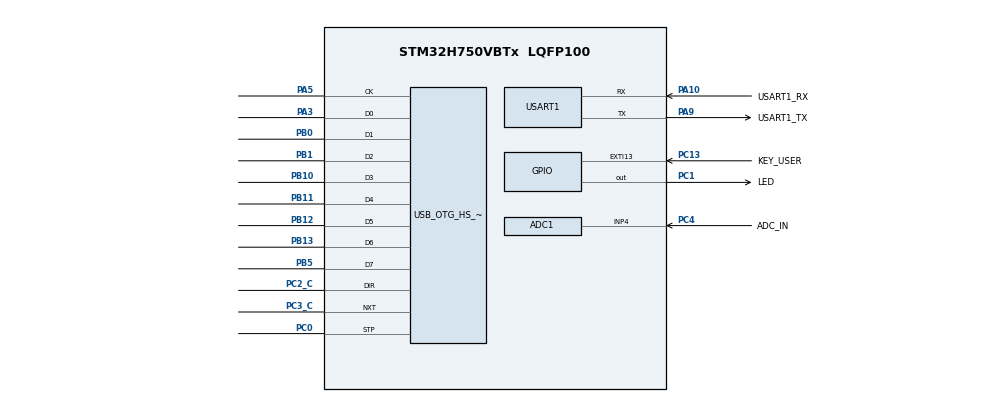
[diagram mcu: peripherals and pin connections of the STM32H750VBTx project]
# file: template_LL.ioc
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ADC1.Channel-4\#ChannelRegularConversion=ADC_CHANNEL_4
ADC1.ContinuousConvMode=DISABLE
ADC1.ConversionDataManagement=ADC_CONVERSIONDATA_DMA_ONESHOT
ADC1.DiscontinuousConvMode=DISABLE
ADC1.EnableRegularConversion=ENABLE
ADC1.ExternalTrigConv=ADC_EXTERNALTRIG_T1_TRGO
ADC1.NbrOfConversion=1
ADC1.NbrOfConversionFlag=1
ADC1.OffsetNumber-4\#ChannelRegularConversion=ADC_OFFSET_NONE
ADC1.OffsetSignedSaturation-4\#ChannelRegularConversion=DISABLE
ADC1.OversamplingMode=DISABLE
ADC1.Rank-4\#ChannelRegularConversion=1
ADC1.SamplingTime-4\#ChannelRegularConversion=ADC_SAMPLETIME_1CYCLE_5
ADC1.master=1
CORTEX_M7.CPU_DCache=Disabled
CORTEX_M7.CPU_ICache=Enabled
Dma.ADC1.0.Direction=DMA_PERIPH_TO_MEMORY
Dma.ADC1.0.EventEnable=DISABLE
Dma.ADC1.0.FIFOMode=DMA_FIFOMODE_DISABLE
Dma.ADC1.0.Instance=DMA1_Stream0
Dma.ADC1.0.MemDataAlignment=DMA_MDATAALIGN_HALFWORD
Dma.ADC1.0.MemInc=DMA_MINC_ENABLE
Dma.ADC1.0.Mode=DMA_NORMAL
Dma.ADC1.0.PeriphDataAlignment=DMA_PDATAALIGN_HALFWORD
Dma.ADC1.0.PeriphInc=DMA_PINC_DISABLE
Dma.ADC1.0.Polarity=HAL_DMAMUX_REQ_GEN_RISING
Dma.ADC1.0.Priority=DMA_PRIORITY_VERY_HIGH
Dma.ADC1.0.RequestNumber=1
Dma.ADC1.0.SignalID=NONE
Dma.ADC1.0.SyncEnable=DISABLE
Dma.ADC1.0.SyncPolarity=HAL_DMAMUX_SYNC_NO_EVENT
Dma.ADC1.0.SyncRequestNumber=1
Dma.ADC1.0.SyncSignalID=NONE
Dma.Request0=ADC1
Mcu.Family=STM32H7
Mcu.Name=STM32H750VBTx
Mcu.Package=LQFP100
NVIC.DMA1_Stream0_IRQn=true\:0\:1\:true\:false\:true\:false\:true\:true
NVIC.EXTI15_10_IRQn=true\:1\:3\:true\:false\:true\:true\:true\:true
NVIC.OTG_HS_IRQn=true\:0\:2\:false\:false\:true\:false\:true\:true
NVIC.PriorityGroup=NVIC_PRIORITYGROUP_2
NVIC.TIM2_IRQn=true\:2\:2\:true\:false\:true\:true\:true\:true
NVIC.USART1_IRQn=true\:3\:2\:true\:false\:true\:true\:true\:true
PA10.GPIO_Label=USART1_RX
PA10.Mode=Asynchronous
PA10.Signal=USART1_RX
PA13\ (JTMS/SWDIO).Mode=Serial_Wire
PA13\ (JTMS/SWDIO).Signal=DEBUG_JTMS-SWDIO
PA14\ (JTCK/SWCLK).Mode=Serial_Wire
PA14\ (JTCK/SWCLK).Signal=DEBUG_JTCK-SWCLK
PA3.Mode=Device_HS
PA3.Signal=USB_OTG_HS_ULPI_D0
PA5.Mode=Device_HS
PA5.Signal=USB_OTG_HS_ULPI_CK
PA9.GPIO_Label=USART1_TX
PA9.Mode=Asynchronous
PA9.Signal=USART1_TX
PB0.Mode=Device_HS
PB0.Signal=USB_OTG_HS_ULPI_D1
PB1.Mode=Device_HS
PB1.Signal=USB_OTG_HS_ULPI_D2
PB10.Mode=Device_HS
PB10.Signal=USB_OTG_HS_ULPI_D3
PB11.Mode=Device_HS
PB11.Signal=USB_OTG_HS_ULPI_D4
PB12.Mode=Device_HS
PB12.Signal=USB_OTG_HS_ULPI_D5
PB13.Mode=Device_HS
PB13.Signal=USB_OTG_HS_ULPI_D6
PB5.Mode=Device_HS
PB5.Signal=USB_OTG_HS_ULPI_D7
PC0.Mode=Device_HS
PC0.Signal=USB_OTG_HS_ULPI_STP
PC1.GPIO_Label=LED
PC1.Signal=GPIO_Output
PC13.GPIO_Label=KEY_USER
PC13.GPIO_ModeDefaultEXTI=GPIO_MODE_IT_FALLING
PC13.GPIO_PuPd=GPIO_PULLUP
PC13.Signal=GPXTI13
PC2_C.Mode=Device_HS
PC2_C.Signal=USB_OTG_HS_ULPI_DIR
PC3_C.Mode=Device_HS
PC3_C.Signal=USB_OTG_HS_ULPI_NXT
PC4.GPIO_Label=ADC_IN
PC4.Signal=ADCx_INP4
PH0-OSC_IN\ (PH0).Mode=HSE-External-Oscillator
PH0-OSC_IN\ (PH0).Signal=RCC_OSC_IN
PH1-OSC_OUT\ (PH1).Mode=HSE-External-Oscillator
PH1-OSC_OUT\ (PH1).Signal=RCC_OSC_OUT
ProjectManager.HeapSize=0x400
ProjectManager.StackSize=0x400
ProjectManager.TargetToolchain=MDK-ARM V5.32
RCC.ADCFreq_Value=8000000
RCC.APB1Freq_Value=100000000
RCC.APB2Freq_Value=100000000
RCC.APB3Freq_Value=100000000
RCC.APB4Freq_Value=100000000
RCC.CortexFreq_Value=50000000
RCC.Cortex_Div=SYSTICK_CLKSOURCE_HCLK_DIV8
RCC.D1PPRE=RCC_APB3_DIV2
RCC.D2PPRE1=RCC_APB1_DIV2
RCC.D2PPRE2=RCC_APB2_DIV2
RCC.D3PPRE=RCC_APB4_DIV2
RCC.DIVM1=5
RCC.DIVM2=25
RCC.DIVM3=5
RCC.DIVN1=160
RCC.DIVN2=320
RCC.DIVN3=96
RCC.DIVP2=40
RCC.DIVQ2=4
RCC.DIVQ3=10
RCC.HCLKFreq_Value=200000000
RCC.HPRE=RCC_HCLK_DIV2
RCC.PLL2FRACN=0
RCC.PLL3FRACN=0
RCC.PLLFRACN=0
RCC.PLLSourceVirtual=RCC_PLLSOURCE_HSE
RCC.SYSCLKFreq_VALUE=400000000
RCC.SYSCLKSource=RCC_SYSCLKSOURCE_PLLCLK
RCC.USBCLockSelection=RCC_USBCLKSOURCE_PLL3
RCC.USBFreq_Value=48000000
SH.ADCx_INP4.0=ADC1_INP4,IN4-Single-Ended
TIM1.AutoReloadPreload=TIM_AUTORELOAD_PRELOAD_ENABLE
TIM1.Period=20000-1
TIM1.TIM_MasterOutputTrigger=TIM_TRGO_UPDATE
TIM1.TIM_MasterSlaveMode=TIM_MASTERSLAVEMODE_DISABLE
TIM2.Period=149
TIM2.Prescaler=19999
TIM2.TIM_MasterOutputTrigger=TIM_TRGO_RESET
USART1.VirtualMode-Asynchronous=VM_ASYNC
USB_DEVICE.CLASS_NAME_HS=CDC
USB_DEVICE.VirtualMode-CDC_HS=Cdc
USB_DEVICE.VirtualModeHS=Cdc_HS
USB_OTG_HS.VirtualMode-Device_HS=Device_HS
VP_TIM1_VS_ClockSourceINT.Mode=Internal
VP_TIM2_VS_ClockSourceINT.Mode=Internal
VP_USB_DEVICE_VS_USB_DEVICE_CDC_HS.Mode=CDC_HS
board=custom

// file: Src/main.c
/* USER CODE BEGIN Header */
/**
  ******************************************************************************
  * @file           : main.c
  * @brief          : Main program body
  ******************************************************************************
  * @attention
  *
  * Copyright (c) 2023 STMicroelectronics.
  * All rights reserved.
  *
  * This software is licensed under terms that can be found in the LICENSE file
  * in the root directory of this software component.
  * If no LICENSE file comes with this software, it is provided AS-IS.
  *
  ******************************************************************************
  */
/* USER CODE END Header */
#include "main.h"
#include "adc.h"
#include "dma.h"
#include "tim.h"
#include "usart.h"
#include "usb_device.h"
#include "gpio.h"

/* USER CODE BEGIN Includes */
#include "Led.h"
#include "Usart1.h"
#include "Usb.h"
#include "DMA_ADC_TIM.h"
#include "Exti_Key.h"

/* USER CODE END Includes */

void SystemClock_Config(void);
void PeriphCommonClock_Config(void);

int main(void)
{

  /* Enable I-Cache---------------------------------------------------------*/
  SCB_EnableICache();

  /* MCU Configuration--------------------------------------------------------*/

  /* Reset of all peripherals, Initializes the Flash interface and the Systick. */
  HAL_Init();

  /* Configure the system clock */
  SystemClock_Config();

/* Configure the peripherals common clocks */
  PeriphCommonClock_Config();

  /* Initialize all configured peripherals */
  MX_GPIO_Init();
  MX_DMA_Init();
  MX_USB_DEVICE_Init();
  MX_ADC1_Init();
  MX_USART1_UART_Init();
  MX_TIM1_Init();
  MX_TIM2_Init();
  /* USER CODE BEGIN 2 */
	Exti_Key_Timer_Init();
	DMA_ADC_TIM_Init();
  /* USER CODE END 2 */

  /* Infinite loop */
  /* USER CODE BEGIN WHILE */
  while (1)
  {
		if(DMA_ADC_Enable_Flag==1)
		{
			DMA_ADC_TIM_Enable();
		}
		if(USB_Transfer_Enable_Flag==1)
		{
			usb_sendHalfwords(ADC_Value_Buffer, UserTxBufferHS, ADC_BUFFER_SIZE, &USB_Transfer_Enable_Flag,1);
		}
		LL_mDelay(10);
    /* USER CODE END WHILE */

  }
}

void SystemClock_Config(void)
{
  LL_FLASH_SetLatency(LL_FLASH_LATENCY_2);
  while(LL_FLASH_GetLatency()!= LL_FLASH_LATENCY_2)
  {
  }
  LL_PWR_ConfigSupply(LL_PWR_LDO_SUPPLY);
  LL_PWR_SetRegulVoltageScaling(LL_PWR_REGU_VOLTAGE_SCALE1);
  while (LL_PWR_IsActiveFlag_VOS() == 0)
  {
  }
  LL_RCC_HSE_Enable();

   /* Wait till HSE is ready */
  while(LL_RCC_HSE_IsReady() != 1)
  {

  }
  LL_RCC_PLL_SetSource(LL_RCC_PLLSOURCE_HSE);
  LL_RCC_PLL1P_Enable();
  LL_RCC_PLL1R_Enable();
  LL_RCC_PLL1_SetVCOInputRange(LL_RCC_PLLINPUTRANGE_4_8);
  LL_RCC_PLL1_SetVCOOutputRange(LL_RCC_PLLVCORANGE_WIDE);
  LL_RCC_PLL1_SetM(5);
  LL_RCC_PLL1_SetN(160);
  LL_RCC_PLL1_SetP(2);
  LL_RCC_PLL1_SetQ(2);
  LL_RCC_PLL1_SetR(2);
  LL_RCC_PLL1_Enable();

   /* Wait till PLL is ready */
  while(LL_RCC_PLL1_IsReady() != 1)
  {
  }

   /* Intermediate AHB prescaler 2 when target frequency clock is higher than 80 MHz */
   LL_RCC_SetAHBPrescaler(LL_RCC_AHB_DIV_2);

  LL_RCC_SetSysClkSource(LL_RCC_SYS_CLKSOURCE_PLL1);

   /* Wait till System clock is ready */
  while(LL_RCC_GetSysClkSource() != LL_RCC_SYS_CLKSOURCE_STATUS_PLL1)
  {

  }
  LL_RCC_SetSysPrescaler(LL_RCC_SYSCLK_DIV_1);
  LL_RCC_SetAHBPrescaler(LL_RCC_AHB_DIV_2);
  LL_RCC_SetAPB1Prescaler(LL_RCC_APB1_DIV_2);
  LL_RCC_SetAPB2Prescaler(LL_RCC_APB2_DIV_2);
  LL_RCC_SetAPB3Prescaler(LL_RCC_APB3_DIV_2);
  LL_RCC_SetAPB4Prescaler(LL_RCC_APB4_DIV_2);
  LL_SetSystemCoreClock(400000000);

   /* Update the time base */
  if (HAL_InitTick (TICK_INT_PRIORITY) != HAL_OK)
  {
    Error_Handler();
  }
}

void PeriphCommonClock_Config(void)
{
  LL_RCC_PLL2P_Enable();
  LL_RCC_PLL2_SetVCOInputRange(LL_RCC_PLLINPUTRANGE_1_2);
  LL_RCC_PLL2_SetVCOOutputRange(LL_RCC_PLLVCORANGE_WIDE);
  LL_RCC_PLL2_SetM(25);
  LL_RCC_PLL2_SetN(320);
  LL_RCC_PLL2_SetP(40);
  LL_RCC_PLL2_SetQ(4);
  LL_RCC_PLL2_SetR(2);
  LL_RCC_PLL2_Enable();

   /* Wait till PLL is ready */
  while(LL_RCC_PLL2_IsReady() != 1)
  {
  }

  LL_RCC_PLL3Q_Enable();
  LL_RCC_PLL3_SetVCOInputRange(LL_RCC_PLLINPUTRANGE_4_8);
  LL_RCC_PLL3_SetVCOOutputRange(LL_RCC_PLLVCORANGE_WIDE);
  LL_RCC_PLL3_SetM(5);
  LL_RCC_PLL3_SetN(96);
  LL_RCC_PLL3_SetP(2);
  LL_RCC_PLL3_SetQ(10);
  LL_RCC_PLL3_SetR(2);
  LL_RCC_PLL3_Enable();

   /* Wait till PLL is ready */
  while(LL_RCC_PLL3_IsReady() != 1)
  {
  }

}

void Error_Handler(void)
{
  __disable_irq();
  while (1)
  {
  }
}
